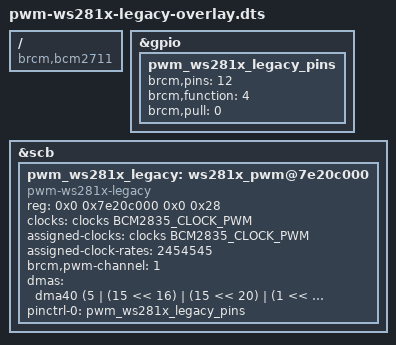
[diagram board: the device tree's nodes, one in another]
/dts-v1/;
/plugin/;

#include <dt-bindings/clock/bcm2835.h>

/ {
	compatible = "brcm,bcm2711";

	fragment@0 {
		target = <&gpio>;

		__overlay__ {
			pwm_ws281x_legacy_pins: pwm_ws281x_legacy_pins {
				brcm,pins = <12>;
				brcm,function = <4>; /* Alt0 */
				brcm,pull = <0>;     /* none */
			};
		};
	};

	fragment@1 {
		target = <&scb>;

		__overlay__ {
			#address-cells = <2>;
			#size-cells = <2>;

			pwm_ws281x_legacy: ws281x_pwm@7e20c000 {
				compatible = "pwm-ws281x-legacy";
				reg = <0x0 0x7e20c000 0x0 0x28>;
				clocks = <&clocks BCM2835_CLOCK_PWM>;
				assigned-clocks = <&clocks BCM2835_CLOCK_PWM>;
				assigned-clock-rates = <2454545>;
				brcm,pwm-channel = <1>;
				dmas = <&dma40 (5 | (15 << 16) | (15 << 20) | (1 << 28))>;
				dma-names = "pwm0";
				pinctrl-names = "default";
				pinctrl-0 = <&pwm_ws281x_legacy_pins>;
				status = "okay";
			};
		};
	};

	__overrides__ {
		pin     = <&pwm_ws281x_legacy_pins>,"brcm,pins:0";
		func    = <&pwm_ws281x_legacy_pins>,"brcm,function:0";
		channel = <&pwm_ws281x_legacy>,"brcm,pwm-channel:0";
	};
};
